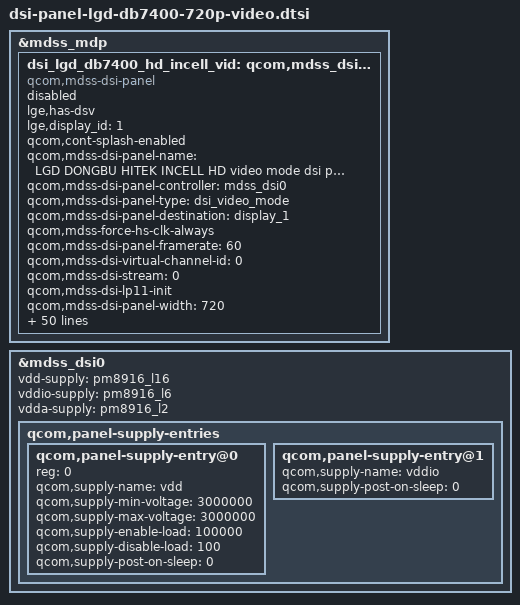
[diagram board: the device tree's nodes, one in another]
&mdss_mdp {
	dsi_lgd_db7400_hd_incell_vid: qcom,mdss_dsi_lgd_incell_db7400_hd_video{
		lge,has-dsv;
		lge,display_id = <1>; 
		compatible = "qcom,mdss-dsi-panel";
		status = "disable";
		qcom,cont-splash-enabled;
		qcom,mdss-dsi-panel-name = "LGD DONGBU HITEK INCELL HD video mode dsi panel";
		qcom,mdss-dsi-panel-controller = <&mdss_dsi0>;
		qcom,mdss-dsi-panel-type = "dsi_video_mode";
		qcom,mdss-dsi-panel-destination = "display_1";
		qcom,mdss-force-hs-clk-always;
		qcom,mdss-dsi-panel-framerate = <60>;
		qcom,mdss-dsi-virtual-channel-id = <0>;
		qcom,mdss-dsi-stream = <0>;
		qcom,mdss-dsi-lp11-init;
		qcom,mdss-dsi-panel-width = <720>;
		qcom,mdss-dsi-panel-height = <1280>;
		qcom,mdss-dsi-h-front-porch = <72>;//<40>;//<84>;
		qcom,mdss-dsi-h-back-porch = <120>;//<80>;//<70>;//<88>;
		qcom,mdss-dsi-h-pulse-width = <4>;
		qcom,mdss-dsi-h-sync-skew = <0>;
		qcom,mdss-dsi-v-front-porch = <580>;//<550>;//<400>;//<7>;
		qcom,mdss-dsi-v-back-porch = <11>;//<417>;
		qcom,mdss-dsi-v-pulse-width = <1>;//<4>;
		qcom,mdss-dsi-h-left-border = <0>;
		qcom,mdss-dsi-h-right-border = <0>;
		qcom,mdss-dsi-v-top-border = <0>;
		qcom,mdss-dsi-v-bottom-border = <0>;
		qcom,mdss-pan-physical-width-dimension = < 71 >; 
		qcom,mdss-pan-physical-height-dimension = < 126 >; 
		qcom,mdss-dsi-bpp = <24>;
		qcom,mdss-dsi-color-order = "rgb_swap_rgb";
		qcom,mdss-dsi-underflow-color = <0>;
		qcom,mdss-dsi-border-color = <0>;
		qcom,mdss-dsi-on-command = [
			15 01 00 00 00 00 02 /*address*/
			36 00

			15 01 00 00 00 00 02 /*manufacturer*/
			B0 00

			29 01 00 00 00 00 03 /*RGB interface*/
			B1 00 46

			29 01 00 00 00 00 07 /*module charateristic set*/
			B2 50 00 0C 00 00 00

			29 01 00 00 00 00 05 /*internal timgin set*/
			B3 4F 80 32 56 

			29 01 00 00 00 00 07/*channel control*/
			B4 05 04 02 28 11 00

			29 01 00 00 00 00 34 /*GIP Control Set*/
			B5 19 04 1C 22 2F 80 
			2F 1F 04 40 05 00 20 
			09 04 40 05 00 A5 0D 
			2F 2F 3F FF 3F FF 01 
			7C 00 02 50 23 40 15 
			6C CB BA A9 97 8D 1F 
			23 40 15 6C CB BA A9 
			97 8D 1F

			29 01 00 00 00 00 03 /*touch enable*/
			B6 01 03

			29 01 00 00 00 00 04 /*gvddp*/
			B7 00 3D 3E 

			29 01 00 00 00 00 03 /*vcom*/
			BA 00 49

			29 01 00 00 00 00 10 /*vghl*/
			BB 00 94 8B 00 00 00 
			00 00 00 00 00 00 00 
			00 13

			29 01 00 00 00 00 03
			BD 04 33

			15 01 00 00 00 00 02 /*vci1*/
			BE 44

			29 01 00 00 00 00 07 /*write dsi control*/
			95 00 08 10 00 00 00
			
			29 01 00 00 00 00 03 /*mipi parameter setting*/
			C6 0A 00
			
			29 01 00 00 00 00 02 /*add temp*/
			CF 0F

			29 01 00 00 00 00 1B /*touch gip control*/
			D7 01 13 FF 39 0B 04 
			14 F4 01 00 00 00 00 
			60 01 67 67 47 10 10
			34 00 00 00 00 00

			29 01 00 00 00 00 06
			F5 00 06 00 00 80

			29 01 00 00 00 00 02 /*vdd1 regulator*/
			F6 06

			29 01 00 00 00 00 04/*sharpness enhance*/
			81 18 34 00

			29 01 00 00 00 00 22/*contrast enhance*/
			83 10 00 07 0F 17 1F 
			27 2F 37 3F 47 4F 57 
			5F 67 6F 77 7F 87 8F 
			97 9F A7 AF B7 BF C7 
			CF D7 DF E7 EF F5

			29 01 00 00 00 00 24/*power sequence control*/
			F0 18 00 00 14 00 00 
			00 01 00 03 2B 01 02 
			53 58 5D 62 A6 AB B0 
			B0 B0 AF B0 AD 85 B0 
			B0 5D 58 53 4E 0A 05 
			00

			29 01 00 00 00 00 0A /*pos gamma curve red*/
			D0 70 06 65 00 08 00 
			71 13 04 

			29 01 00 00 00 00 0A /*neg gamma curve red*/
			D1 40 05 75 00 04 01 
			61 23 03 

			29 01 00 00 00 00 0A /*pos gamma curve green*/
			D2 70 06 65 00 08 00 
			71 13 04 

			29 01 00 00 00 00 0A /*neg gamma curve green*/
			D3 40 05 75 00 04 01 
			61 23 03 

			29 01 00 00 00 00 0A /*pos gamma curve blue*/
			D4 70 06 65 00 08 00 
			71 13 04 

			29 01 00 00 3C 00 0A /*neg gamma curve blue*/
			D5 40 04 75 00 04 01 
			61 23 03 

			05 01 00 00 A0 00 01 /*exit sleep*/
			11
			
			05 01 00 00 28 00 01 /*display on*/
			29
			
		];
		qcom,mdss-dsi-on-command-for-glanceview = [

			29 01 00 00 00 00 34 /*GIP Control Set*/
			B5 19 04 1C 22 2F 80
			2F 1F 04 40 05 00 20
			09 04 40 05 00 A5 0D
			2F 2F 3F FF 3F FF 01
			7C 00 02 50 23 40 15
			6C CB BA A9 97 8D 1F
			23 40 15 6C CB BA A9
			97 8D 1F

			29 01 00 00 00 00 03 /*touch enable*/
			B6 01 03

			29 01 00 00 14 00 03 /*mipi lane floating*/
			C8 00 00

			29 01 00 00 00 00 02 /*add temp*/
			CF 0F

			29 01 00 00 00 00 1B /*touch gip control*/
			D7 01 13 FF 39 0B 04
			14 F4 01 00 00 00 00
			60 01 67 67 47 10 10
			34 00 00 00 00 00

			29 01 00 00 00 00 06
			F5 00 06 00 00 80

			05 01 00 00 05 00 01 /*exit sleep*/
			11

			05 01 00 00 05 00 01 /*display on*/
			29

		];
		qcom,mdss-dsi-off-command1 = [
			05 01 00 00 28 00 01 /*display off*/
			28
			05 01 00 00 28 00 01 /*Sleep in*/
			10
		];
		qcom,mdss-dsi-off-command2 = [
			29 01 00 00 00 00 1C /*34->1C GIP Control Set*/
			B5 19 04 1C 22 2F 80
			2F 1F 04 40 05 00 20
			09 04 40 05 00 A5 0D
			2F 1F 04 00 04 00 00
//			7C 00 02 50 23 40 15
//			6C CB BA A9 97 8D 1F
//			23 40 15 6C CB BA A9
//			97 8D 1F

			29 01 00 00 00 00 03 /*touch enable*/
			B6 01 01

			29 01 00 00 00 00 02 /*add temp*/
			CF 07

			29 01 00 00 00 00 1B /*touch gip control*/
			D7 01 13 FF 39 0B 04 
			14 F4 01 00 00 00 00 
			40 01 67 67 47 10 10
			34 00 00 00 00 00

			29 01 00 00 00 00 06/*Touch LFD Control set*/
			F5 00 06 00 00 C0

			29 01 00 00 14 00 03 /*mipi lane floating*/
			C8 01 00
		];
		qcom,mdss-dsi-on-command-state = "dsi_lp_mode";
		qcom,mdss-dsi-off-command-state = "dsi_hs_mode";
		qcom,mdss-dsi-lut-update-command-state = "dsi_hs_mode";
		qcom,mdss-dsi-h-sync-pulse = <0>;
		qcom,mdss-dsi-traffic-mode = "non_burst_sync_event";
		qcom,mdss-dsi-lane-map = "lane_map_0123";
		//qcom,mdss-dsi-hfp-power-mode;
		//qcom,mdss-dsi-hbp-power-mode;
		//qcom,mdss-dsi-hsa-power-mode;
		qcom,mdss-dsi-bllp-eof-power-mode;
		qcom,mdss-dsi-bllp-power-mode;
		qcom,mdss-dsi-last-line-interleave;
		qcom,mdss-dsi-lane-0-state;
		qcom,mdss-dsi-lane-1-state;
		qcom,mdss-dsi-lane-2-state;
		qcom,mdss-dsi-lane-3-state;
		qcom,mdss-dsi-panel-timings = [A8 26 1A 00 50 4A 28 2A 3E 03 04 00];
		qcom,mdss-dsi-t-clk-post = <0x03>;
		qcom,mdss-dsi-t-clk-pre = <0x24>;


		qcom,mdss-dsi-bl-min-level = <1>;
		qcom,mdss-dsi-bl-max-level = <255>;
		qcom,mdss-dsi-dma-trigger = "trigger_sw";
		qcom,mdss-dsi-mdp-trigger = "none";
		qcom,mdss-dsi-reset-sequence = <1 5>;
	};
};

&mdss_dsi0 {
    vdd-supply = <&pm8916_l16>;
    vddio-supply = <&pm8916_l6>;
    vdda-supply = <&pm8916_l2>;
    qcom,panel-supply-entries {
        qcom,panel-supply-entry@0 {
            reg = <0>;
            qcom,supply-name = "vdd";
            qcom,supply-min-voltage = <3000000>;
            qcom,supply-max-voltage = <3000000>;
            qcom,supply-enable-load = <100000>;
            qcom,supply-disable-load = <100>;
            qcom,supply-post-on-sleep = <0>;
        };
        qcom,panel-supply-entry@1 {
            qcom,supply-name = "vddio";
            qcom,supply-post-on-sleep = <0>;
        };
    };
};

